AUTOSAR XML (schema 00044)
package /ComponentTypes
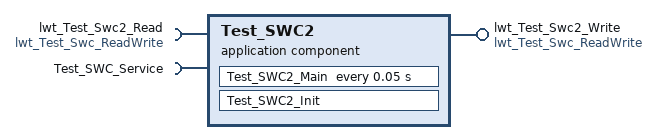
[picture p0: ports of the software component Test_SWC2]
  application sw component type Test_SWC2
    provide port lwt_Test_Swc2_Write: nonqueued-sender-com-spec{data-element=u8_Signal_lwt, init-value=0}, provided-interface=lwt_Test_Swc_ReadWrite
    require port lwt_Test_Swc2_Read: nonqueued-receiver-com-spec{data-element=u8_Signal_lwt, init-value=0}, required-interface=lwt_Test_Swc_ReadWrite
    require port Test_SWC_Service: client-com-spec=Operation_lwt, required-interface=Test_SWC_Service
    behavior Test_SWC2_InternalBehavior
      init event Test_SWC2_InitEvent: start-on-event=Test_SWC2_Init
      timing event TMT_Test_SWC2_Main: start-on-event=Test_SWC2_Main, period=0.05
      runnable Test_SWC2_Main: minimum-start-interval=0.05
        data-receive-point-by-arguments:
          access REC_lwt_Test_Swc_Read_u8_Signal_lwt: accessed-variable=lwt_Test_Swc2_Read.u8_Signal_lwt
        data-send-points:
          access SEND_lwt_Test_Swc_Write_u8_Signal_lwt: accessed-variable=lwt_Test_Swc2_Write.u8_Signal_lwt
        sync call SC_Test_SWC_Service_Operation_lwt: operation=Test_SWC_Service.Operation_lwt
      runnable Test_SWC2_Init
  swc implementation Test_SWC2_Implementation: behavior=Test_SWC2_InternalBehavior
